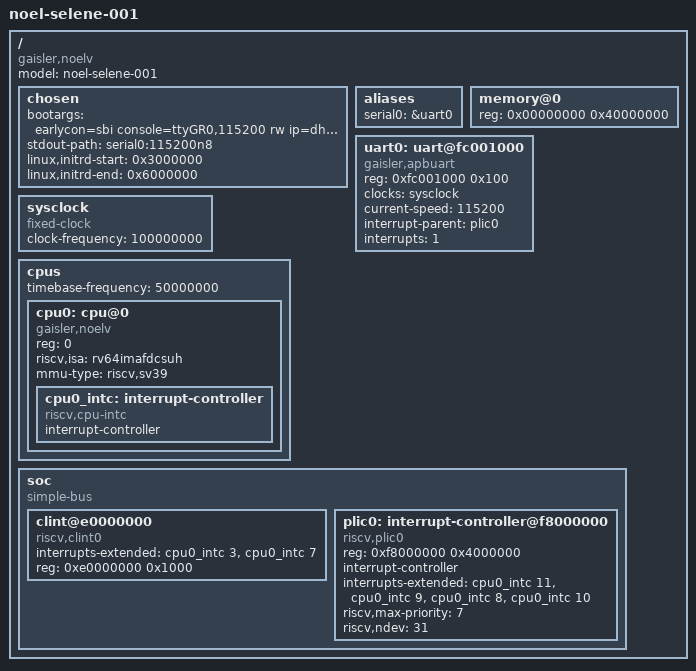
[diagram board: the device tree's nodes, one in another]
/dts-v1/;

/ {
	#address-cells = <1>;
	#size-cells = <1>;
	model = "noel-selene-001";
	compatible = "gaisler,noelv";

	chosen {
		bootargs = "earlycon=sbi console=ttyGR0,115200 rw ip=dhcp mem=768M";
		stdout-path = "serial0:115200n8";
		linux,initrd-start = <0x3000000>;
		linux,initrd-end = <0x6000000>;
	};

	aliases {
		serial0 = &uart0;
	};

	memory@0 {
		device_type = "memory";
		reg = <0x00000000 0x40000000>;
	};

	uart0: uart@fc001000 {
		compatible = "gaisler,apbuart";
		reg = <0xfc001000 0x100>;
		clocks = <&sysclock>;
		current-speed = <115200>;
		interrupt-parent = <&plic0>;
		interrupts = <1>;
	};

	sysclock: sysclock {
		#clock-cells = <0>;
		compatible = "fixed-clock";
		clock-frequency = <100000000>;
	};

	cpus {
		#address-cells = <1>;
		#size-cells = <0>;
		timebase-frequency = <50000000>;

		cpu0: cpu@0 {
			device_type = "cpu";
			reg = <0>;
			status = "okay";
			compatible = "gaisler,noelv", "riscv";
			riscv,isa = "rv64imafdcsuh";
			mmu-type = "riscv,sv39";

			cpu0_intc: interrupt-controller {
				#address-cells = <0>;
				#interrupt-cells = <1>;
				interrupt-controller;
				compatible = "riscv,cpu-intc";
			};
		};
/* MULTICORE
		cpu1: cpu@1 {
			device_type = "cpu";
			reg = <1>;
			status = "okay";
			compatible = "gaisler,noelv", "riscv";
			riscv,isa = "rv64imafdcsuh";
			mmu-type = "riscv,sv39";
			cpu1_intc: interrupt-controller {
				#address-cells = <0>;
				#interrupt-cells = <1>;
				interrupt-controller;
				compatible = "riscv,cpu-intc";
			};
		};
		cpu2: cpu@2 {
			device_type = "cpu";
			reg = <2>;
			status = "okay";
			compatible = "gaisler,noelv", "riscv";
			riscv,isa = "rv64imafdcsuh";
			mmu-type = "riscv,sv39";
			cpu2_intc: interrupt-controller {
				#address-cells = <0>;
				#interrupt-cells = <1>;
				interrupt-controller;
				compatible = "riscv,cpu-intc";
			};
		};
		cpu3: cpu@3 {
			device_type = "cpu";
			reg = <3>;
			status = "okay";
			compatible = "gaisler,noelv", "riscv";
			riscv,isa = "rv64imafdcsuh";
			mmu-type = "riscv,sv39";
			cpu3_intc: interrupt-controller {
				#address-cells = <0>;
				#interrupt-cells = <1>;
				interrupt-controller;
				compatible = "riscv,cpu-intc";
			};
		};
		cpu4: cpu@4 {
			device_type = "cpu";
			reg = <4>;
			status = "okay";
			compatible = "gaisler,noelv", "riscv";
			riscv,isa = "rv64imafdcsuh";
			mmu-type = "riscv,sv39";
			cpu4_intc: interrupt-controller {
				#address-cells = <0>;
				#interrupt-cells = <1>;
				interrupt-controller;
				compatible = "riscv,cpu-intc";
			};
		};
		cpu5: cpu@5 {
			device_type = "cpu";
			reg = <5>;
			status = "okay";
			compatible = "gaisler,noelv", "riscv";
			riscv,isa = "rv64imafdcsuh";
			mmu-type = "riscv,sv39";
			cpu5_intc: interrupt-controller {
				#address-cells = <0>;
				#interrupt-cells = <1>;
				interrupt-controller;
				compatible = "riscv,cpu-intc";
			};
		};
MULTICORE */
  };

	soc {
		#address-cells = <1>;
		#size-cells = <1>;
		compatible = "simple-bus";
		ranges;
		
		clint@e0000000 {
			compatible = "riscv,clint0";
			interrupts-extended = <
				&cpu0_intc 3
				&cpu0_intc 7
/* MULTICORE
				&cpu1_intc 3
				&cpu1_intc 7
				&cpu2_intc 3
				&cpu2_intc 7
				&cpu3_intc 3
				&cpu3_intc 7
				&cpu4_intc 3
				&cpu4_intc 7
				&cpu5_intc 3
				&cpu5_intc 7
MULTICORE */
			>;
			reg = <0xe0000000 0x1000>;
			reg-names = "control";
		};

		plic0: interrupt-controller@f8000000 {
			#address-cells = <0>;
			#interrupt-cells = <1>;
			compatible = "riscv,plic0";
			reg = <0xf8000000 0x4000000>;
			interrupt-controller;
			interrupts-extended = <
				&cpu0_intc 11
				&cpu0_intc 9
				&cpu0_intc 8
				&cpu0_intc 10
/* MULTICORE
				&cpu1_intc 11
				&cpu1_intc 9
				&cpu1_intc 8
				&cpu1_intc 10
				&cpu2_intc 11
				&cpu2_intc 9
				&cpu2_intc 8
				&cpu2_intc 10
				&cpu3_intc 11
				&cpu3_intc 9
				&cpu3_intc 8
				&cpu3_intc 10
				&cpu4_intc 11
				&cpu4_intc 9
				&cpu4_intc 8
				&cpu4_intc 10
				&cpu5_intc 11
				&cpu5_intc 9
				&cpu5_intc 8
				&cpu5_intc 10
MULTICORE */
			>;
			riscv,max-priority = <7>;
			riscv,ndev = <31>;
		};

/* ETHERNET
		greth0: greth@fc084000 {
			compatible = "gaisler,greth";
			reg = <0xfc084000 0x100>;
			interrupt-parent = <&plic0>;
			interrupts = <5>;
			preserve-link = <1>;
			local-mac-address = [00 60 C2 75 a3 52];
		};
ETHERNET */

/*
		grcanfd0: grcanfd@fc0a0000 {
			compatible = "gaisler,grcanfd";
			reg = <0xfc0a0000 0x400>;
			clocks = <&sysclock>;
			interrupt-parent = <&plic0>;
			interrupts = <8>;
		};
		
		grcanfd1: grcanfd@fc0b0000 {
			compatible = "gaisler,grcanfd";
			reg = <0xfc0b0000 0x400>;
			clocks = <&sysclock>;
			interrupt-parent = <&plic0>;
			interrupts = <9>;
		};
		
		grspw0: grspw@fc000600 {
			compatible = "gaisler,grspw2";
			reg = <0xfc000600 0x100>;
			clocks = <&sysclock>;
			interrupt-parent = <&plic0>;
			interrupts = <6>;
		};
		
		grspw1: grspw@fc000700 {
			compatible = "gaisler,grspw2";
			reg = <0xfc000700 0x100>;
			clocks = <&sysclock>;
			interrupt-parent = <&plic0>;
			interrupts = <7>;
		};
*/
	};
};
